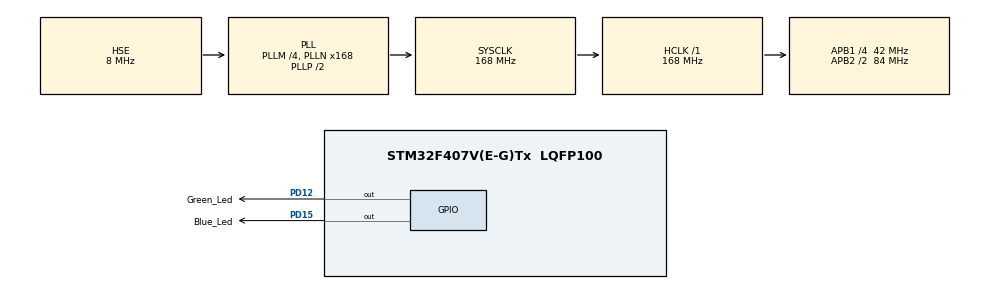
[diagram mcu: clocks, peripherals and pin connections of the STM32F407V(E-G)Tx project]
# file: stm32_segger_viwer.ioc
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Mcu.Family=STM32F4
RCC.PLLSourceVirtual=RCC_PLLSOURCE_HSE
PD12.GPIO_Label=Green_Led
PH0-OSC_IN.Signal=RCC_OSC_IN
RCC.CortexFreq_Value=168000000
FREERTOS.Tasks01=defaultTask,24,128,StartDefaultTask,Default,NULL,Dynamic,NULL,NULL;LedTask,8,128,StartLedTask,Default,NULL,Dynamic,NULL,NULL
PD15.GPIO_Label=Blue_Led
RCC.APB1CLKDivider=RCC_HCLK_DIV4
RCC.SYSCLKSource=RCC_SYSCLKSOURCE_PLLCLK
ProjectManager.StackSize=0x400
VP_FREERTOS_VS_CMSIS_V2.Mode=CMSIS_V2
ProjectManager.TargetToolchain=STM32CubeIDE
RCC.HCLKFreq_Value=168000000
RCC.APB2TimFreq_Value=168000000
RCC.LSE_VALUE=32768
RCC.AHBFreq_Value=168000000
PH0-OSC_IN.Mode=HSE-External-Oscillator
NVIC.TIM1_TRG_COM_TIM11_IRQn=true\:0\:0\:false\:false\:true\:false\:false\:true
RCC.HSE_VALUE=8000000
board=custom
RCC.VCOOutputFreq_Value=336000000
RCC.APB2Freq_Value=84000000
PH1-OSC_OUT.Signal=RCC_OSC_OUT
VP_SYS_VS_tim11.Mode=TIM11
Mcu.Name=STM32F407V(E-G)Tx
PH1-OSC_OUT.Mode=HSE-External-Oscillator
RCC.48MHZClocksFreq_Value=84000000
RCC.SYSCLKFreq_VALUE=168000000
Mcu.Package=LQFP100
NVIC.TimeBase=TIM1_TRG_COM_TIM11_IRQn
PD12.Signal=GPIO_Output
NVIC.TimeBaseIP=TIM11
ProjectManager.HeapSize=0x200
RCC.HSI_VALUE=16000000
NVIC.PriorityGroup=NVIC_PRIORITYGROUP_4
RCC.APB2CLKDivider=RCC_HCLK_DIV2
RCC.PLLM=4
RCC.PLLN=168
RCC.APB1TimFreq_Value=84000000
RCC.APB1Freq_Value=42000000
PD15.Signal=GPIO_Output

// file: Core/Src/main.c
/* USER CODE BEGIN Header */
/**
  ******************************************************************************
  * @file           : main.c
  * @brief          : Main program body
  ******************************************************************************
  * @attention
  *
  * <h2><center>&copy; Copyright (c) 2021 STMicroelectronics.
  * All rights reserved.</center></h2>
  *
  * This software component is licensed by ST under BSD 3-Clause license,
  * the "License"; You may not use this file except in compliance with the
  * License. You may obtain a copy of the License at:
  *                        opensource.org/licenses/BSD-3-Clause
  *
  ******************************************************************************
  */
/* USER CODE END Header */
#include "main.h"
#include "cmsis_os.h"
#include "gpio.h"

/* USER CODE BEGIN Includes */
#include "SEGGER_SYSVIEW.h"
#include "portmacro.h"
/* USER CODE END Includes */

void SystemClock_Config(void);
void MX_FREERTOS_Init(void);

int main(void)
{

  /* MCU Configuration--------------------------------------------------------*/

  /* Reset of all peripherals, Initializes the Flash interface and the Systick. */
  HAL_Init();

  /* Configure the system clock */
  SystemClock_Config();

  /* Initialize all configured peripherals */
  MX_GPIO_Init();
  /* USER CODE BEGIN 2 */

  SEGGER_SYSVIEW_Conf();
  vSetVarulMaxPRIGROUPValue();
  SEGGER_SYSVIEW_Start();

  /* USER CODE END 2 */

  /* Init scheduler */
  osKernelInitialize();  /* Call init function for freertos objects (in freertos.c) */
  MX_FREERTOS_Init();
  /* Start scheduler */
  osKernelStart();

  /* We should never get here as control is now taken by the scheduler */
  /* Infinite loop */
  while (1)
  {

  }
}

void SystemClock_Config(void)
{
  RCC_OscInitTypeDef RCC_OscInitStruct = {0};
  RCC_ClkInitTypeDef RCC_ClkInitStruct = {0};

  /** Configure the main internal regulator output voltage
  */
  __HAL_RCC_PWR_CLK_ENABLE();
  __HAL_PWR_VOLTAGESCALING_CONFIG(PWR_REGULATOR_VOLTAGE_SCALE1);
  /** Initializes the RCC Oscillators according to the specified parameters
  * in the RCC_OscInitTypeDef structure.
  */
  RCC_OscInitStruct.OscillatorType = RCC_OSCILLATORTYPE_HSE;
  RCC_OscInitStruct.HSEState = RCC_HSE_ON;
  RCC_OscInitStruct.PLL.PLLState = RCC_PLL_ON;
  RCC_OscInitStruct.PLL.PLLSource = RCC_PLLSOURCE_HSE;
  RCC_OscInitStruct.PLL.PLLM = 4;
  RCC_OscInitStruct.PLL.PLLN = 168;
  RCC_OscInitStruct.PLL.PLLP = RCC_PLLP_DIV2;
  RCC_OscInitStruct.PLL.PLLQ = 4;
  if (HAL_RCC_OscConfig(&RCC_OscInitStruct) != HAL_OK)
  {
    Error_Handler();
  }
  /** Initializes the CPU, AHB and APB buses clocks
  */
  RCC_ClkInitStruct.ClockType = RCC_CLOCKTYPE_HCLK|RCC_CLOCKTYPE_SYSCLK
                              |RCC_CLOCKTYPE_PCLK1|RCC_CLOCKTYPE_PCLK2;
  RCC_ClkInitStruct.SYSCLKSource = RCC_SYSCLKSOURCE_PLLCLK;
  RCC_ClkInitStruct.AHBCLKDivider = RCC_SYSCLK_DIV1;
  RCC_ClkInitStruct.APB1CLKDivider = RCC_HCLK_DIV4;
  RCC_ClkInitStruct.APB2CLKDivider = RCC_HCLK_DIV2;

  if (HAL_RCC_ClockConfig(&RCC_ClkInitStruct, FLASH_LATENCY_5) != HAL_OK)
  {
    Error_Handler();
  }
}

 /**
  * @brief  Period elapsed callback in non blocking mode
  * @note   This function is called  when TIM11 interrupt took place, inside
  * HAL_TIM_IRQHandler(). It makes a direct call to HAL_IncTick() to increment
  * a global variable "uwTick" used as application time base.
  * @param  htim : TIM handle
  * @retval None
  */
void HAL_TIM_PeriodElapsedCallback(TIM_HandleTypeDef *htim)
{
  if (htim->Instance == TIM11) {
    HAL_IncTick();
  }
}

void Error_Handler(void)
{
  __disable_irq();
  while (1)
  {
  }
}

/************************ (C) COPYRIGHT STMicroelectronics *****END OF FILE****/

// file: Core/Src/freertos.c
/* USER CODE BEGIN Header */
/**
  ******************************************************************************
  * File Name          : freertos.c
  * Description        : Code for freertos applications
  ******************************************************************************
  * @attention
  *
  * <h2><center>&copy; Copyright (c) 2021 STMicroelectronics.
  * All rights reserved.</center></h2>
  *
  * This software component is licensed by ST under Ultimate Liberty license
  * SLA0044, the "License"; You may not use this file except in compliance with
  * the License. You may obtain a copy of the License at:
  *                             www.st.com/SLA0044
  *
  ******************************************************************************
  */
/* USER CODE END Header */

#include "FreeRTOS.h"
#include "task.h"
#include "main.h"
#include "cmsis_os.h"

/* Definitions for defaultTask */
osThreadId_t defaultTaskHandle;
const osThreadAttr_t defaultTask_attributes = {
  .name = "defaultTask",
  .stack_size = 128 * 4,
  .priority = (osPriority_t) osPriorityNormal,
};
/* Definitions for LedTask */
osThreadId_t LedTaskHandle;
const osThreadAttr_t LedTask_attributes = {
  .name = "LedTask",
  .stack_size = 128 * 4,
  .priority = (osPriority_t) osPriorityLow,
};

void StartDefaultTask(void *argument);
void StartLedTask(void *argument);

void MX_FREERTOS_Init(void); /* (MISRA C 2004 rule 8.1) */

void MX_FREERTOS_Init(void) {

  /* Create the thread(s) */
  /* creation of defaultTask */
  defaultTaskHandle = osThreadNew(StartDefaultTask, NULL, &defaultTask_attributes);

  /* creation of LedTask */
  LedTaskHandle = osThreadNew(StartLedTask, NULL, &LedTask_attributes);

}

void StartDefaultTask(void *argument)
{
  /* USER CODE BEGIN StartDefaultTask */
  /* Infinite loop */
  for(;;)
  {
	  HAL_GPIO_TogglePin(Green_Led_GPIO_Port, Green_Led_Pin);

	  for (uint32_t i = 0;  i < 10000; ) {
		  i++;
	}
    osDelay(50);
  }
  /* USER CODE END StartDefaultTask */
}

void StartLedTask(void *argument)
{
  /* USER CODE BEGIN StartLedTask */
  /* Infinite loop */
  for(;;)
  {
	  HAL_GPIO_TogglePin(Blue_Led_GPIO_Port, Blue_Led_Pin);
	  for ( uint32_t i = 0;  i < 10000; ) {
		  i++;
	}
    osDelay(10);
  }
  /* USER CODE END StartLedTask */
}

/************************ (C) COPYRIGHT STMicroelectronics *****END OF FILE****/
